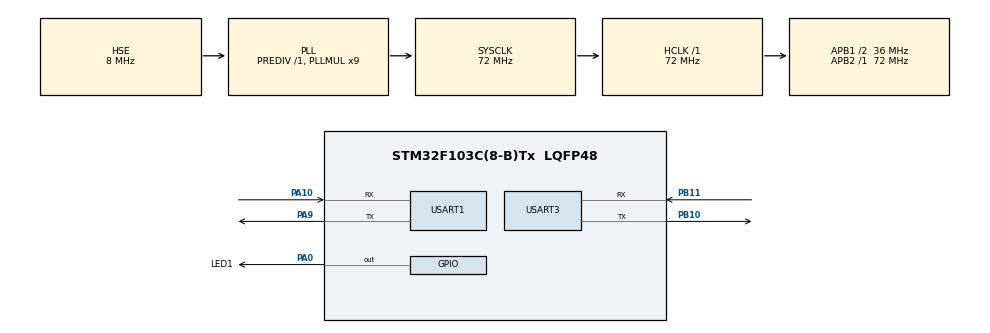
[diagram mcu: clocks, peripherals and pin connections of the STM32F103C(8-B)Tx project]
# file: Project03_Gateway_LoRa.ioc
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Dma.Request0=USART1_RX
Dma.Request1=USART3_RX
Dma.USART1_RX.0.Direction=DMA_PERIPH_TO_MEMORY
Dma.USART1_RX.0.Instance=DMA1_Channel5
Dma.USART1_RX.0.MemDataAlignment=DMA_MDATAALIGN_BYTE
Dma.USART1_RX.0.MemInc=DMA_MINC_ENABLE
Dma.USART1_RX.0.Mode=DMA_NORMAL
Dma.USART1_RX.0.PeriphDataAlignment=DMA_PDATAALIGN_BYTE
Dma.USART1_RX.0.PeriphInc=DMA_PINC_DISABLE
Dma.USART1_RX.0.Priority=DMA_PRIORITY_LOW
Dma.USART3_RX.1.Direction=DMA_PERIPH_TO_MEMORY
Dma.USART3_RX.1.Instance=DMA1_Channel3
Dma.USART3_RX.1.MemDataAlignment=DMA_MDATAALIGN_BYTE
Dma.USART3_RX.1.MemInc=DMA_MINC_ENABLE
Dma.USART3_RX.1.Mode=DMA_NORMAL
Dma.USART3_RX.1.PeriphDataAlignment=DMA_PDATAALIGN_BYTE
Dma.USART3_RX.1.PeriphInc=DMA_PINC_DISABLE
Dma.USART3_RX.1.Priority=DMA_PRIORITY_LOW
Mcu.Family=STM32F1
Mcu.Name=STM32F103C(8-B)Tx
Mcu.Package=LQFP48
NVIC.DMA1_Channel3_IRQn=true\:0\:0\:false\:false\:true\:false\:true\:true
NVIC.DMA1_Channel5_IRQn=true\:0\:0\:false\:false\:true\:false\:true\:true
NVIC.PriorityGroup=NVIC_PRIORITYGROUP_4
NVIC.USART1_IRQn=true\:0\:0\:false\:false\:true\:true\:true\:true
NVIC.USART3_IRQn=true\:0\:0\:false\:false\:true\:true\:true\:true
PA0-WKUP.GPIO_Label=LED1
PA0-WKUP.GPIO_Speed=GPIO_SPEED_FREQ_HIGH
PA0-WKUP.PinState=GPIO_PIN_SET
PA0-WKUP.Signal=GPIO_Output
PA10.Mode=Asynchronous
PA10.Signal=USART1_RX
PA13.Mode=Serial_Wire
PA13.Signal=SYS_JTMS-SWDIO
PA14.Mode=Serial_Wire
PA14.Signal=SYS_JTCK-SWCLK
PA9.Mode=Asynchronous
PA9.Signal=USART1_TX
PB10.Mode=Asynchronous
PB10.Signal=USART3_TX
PB11.Mode=Asynchronous
PB11.Signal=USART3_RX
PC14-OSC32_IN.Mode=LSE-External-Oscillator
PC14-OSC32_IN.Signal=RCC_OSC32_IN
PC15-OSC32_OUT.Mode=LSE-External-Oscillator
PC15-OSC32_OUT.Signal=RCC_OSC32_OUT
PD0-OSC_IN.Mode=HSE-External-Oscillator
PD0-OSC_IN.Signal=RCC_OSC_IN
PD1-OSC_OUT.Mode=HSE-External-Oscillator
PD1-OSC_OUT.Signal=RCC_OSC_OUT
ProjectManager.HeapSize=0x200
ProjectManager.StackSize=0x400
ProjectManager.TargetToolchain=MDK-ARM V5.32
RCC.AHBFreq_Value=72000000
RCC.APB1CLKDivider=RCC_HCLK_DIV2
RCC.APB1Freq_Value=36000000
RCC.APB1TimFreq_Value=72000000
RCC.APB2Freq_Value=72000000
RCC.APB2TimFreq_Value=72000000
RCC.HCLKFreq_Value=72000000
RCC.PLLMUL=RCC_PLL_MUL9
RCC.PLLSourceVirtual=RCC_PLLSOURCE_HSE
RCC.SYSCLKFreq_VALUE=72000000
RCC.SYSCLKSource=RCC_SYSCLKSOURCE_PLLCLK
RCC.USBFreq_Value=72000000
USART1.VirtualMode=VM_ASYNC
USART3.VirtualMode=VM_ASYNC
VP_CRC_VS_CRC.Mode=CRC_Activate
board=custom

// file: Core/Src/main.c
/* USER CODE BEGIN Header */
/**
  ******************************************************************************
  * @file           : main.c
  * @brief          : Main program body
  ******************************************************************************
  * @attention
  *
  * Copyright (c) 2026 STMicroelectronics.
  * All rights reserved.
  *
  * This software is licensed under terms that can be found in the LICENSE file
  * in the root directory of this software component.
  * If no LICENSE file comes with this software, it is provided AS-IS.
  *
  ******************************************************************************
  */
/* USER CODE END Header */
#include "main.h"
#include "crc.h"
#include "dma.h"
#include "usart.h"
#include "gpio.h"

/* USER CODE BEGIN Includes */
#include "lora_buf.h"               /* LoRa 串口帧缓冲层，提供 DMA+IDLE 帧接收队列 */
#include "app_update.h"             /* 网关端 LoRa 更新状态机，管理固件分发流程 */
#include "app_bootloader.h"         /* 网关 Bootloader 辅助定义（分区地址、跳转函数等） */
#include "uart_buf.h"               /* UART DMA+IDLE 帧缓冲，用于串口接收 PC 发送的 .bin 固件 */
#include "fw_cache_conf.h"          /* 固件缓存区配置：FW_CACHE_ADDR(0x08004000) 和大小定义 */
#include <stdio.h>                  /* printf 支持，通过 fputc 重定向到 USART1 输出调试日志 */
/* USER CODE END Includes */

/* USER CODE BEGIN PV */
static LORA_Buf_t lora_ctx;        /* LoRa 串口帧缓冲上下文，管理 USART3 DMA 接收和帧队列 */
static AppUpdate_t update_ctx;     /* 网关更新状态机上下文，驱动 LoRa 固件分发流程 */
/* USER CODE END PV */

void SystemClock_Config(void);

int main(void)
{

  /* MCU Configuration--------------------------------------------------------*/

  /* Reset of all peripherals, Initializes the Flash interface and the Systick. */
  HAL_Init();

  /* Configure the system clock */
  SystemClock_Config();

  /* Initialize all configured peripherals */
  MX_GPIO_Init();
  MX_DMA_Init();
  MX_USART1_UART_Init();
  MX_USART3_UART_Init();
  MX_CRC_Init();
  /* USER CODE BEGIN 2 */

  /*
   * LoRa 串口帧缓冲初始化
   * 绑定 USART3（LoRa 模块通信口）到帧缓冲上下文
   * 启动 DMA Normal 模式 + IDLE 线检测接收，用于接收 LoRa 协议帧
   */
  LORA_Buf_Init(&lora_ctx, &huart3);

  /*
   * 网关端 LoRa 更新状态机初始化
   *
   * 网关的职责是：
   * 1. 通过 USART1 串口从 PC 接收 .bin 固件文件，存储到内部 Flash 缓存区
   * 2. 通过 USART3 LoRa 模块将固件分帧发送给 App 节点
   *
   * FW_CACHE_ADDR = 0x08004000：固件在网关 Flash 中的缓存起始地址
   * 1344：固件大小（当前硬编码，待优化为动态读取）
   */
  AppUpdate_Init(&update_ctx, &lora_ctx,
                 (const uint8_t *)FW_CACHE_ADDR, 1344);

  /*
   * USART1 DMA 接收初始化
   * 用于从 PC 串口接收 .bin 固件数据流（UART 下载协议）
   * USART1 同时用于 printf 调试输出，DMA 仅用于接收方向
   */
  UART_DMA_Rx_Init();
  /* USER CODE END 2 */

  /* Infinite loop */
  while (1)
  {

    /* USER CODE BEGIN 3 */

    /*
     * 网关更新状态机轮询处理
     * 每轮循环检查两路输入：
     * 1. USART1 串口：检查是否有 PC 发来的固件数据（UART 下载协议）
     * 2. USART3 LoRa：检查是否有 App 节点发来的 UPDATE_REQ 等协议帧
     * 根据状态机当前状态驱动固件分发流程
     * 主循环不能有阻塞延时，以保证串口帧和 LoRa 帧都能及时处理
     */
    AppUpdate_Poll(&update_ctx);
  }
  /* USER CODE END 3 */
}

void SystemClock_Config(void)
{
  RCC_OscInitTypeDef RCC_OscInitStruct = {0};
  RCC_ClkInitTypeDef RCC_ClkInitStruct = {0};

  /** Initializes the RCC Oscillators according to the specified parameters
  * in the RCC_OscInitTypeDef structure.
  */
  RCC_OscInitStruct.OscillatorType = RCC_OSCILLATORTYPE_HSE;
  RCC_OscInitStruct.HSEState = RCC_HSE_ON;
  RCC_OscInitStruct.HSEPredivValue = RCC_HSE_PREDIV_DIV1;
  RCC_OscInitStruct.HSIState = RCC_HSI_ON;
  RCC_OscInitStruct.PLL.PLLState = RCC_PLL_ON;
  RCC_OscInitStruct.PLL.PLLSource = RCC_PLLSOURCE_HSE;
  RCC_OscInitStruct.PLL.PLLMUL = RCC_PLL_MUL9;
  if (HAL_RCC_OscConfig(&RCC_OscInitStruct) != HAL_OK)
  {
    Error_Handler();
  }

  /** Initializes the CPU, AHB and APB buses clocks
  */
  RCC_ClkInitStruct.ClockType = RCC_CLOCKTYPE_HCLK|RCC_CLOCKTYPE_SYSCLK
                              |RCC_CLOCKTYPE_PCLK1|RCC_CLOCKTYPE_PCLK2;
  RCC_ClkInitStruct.SYSCLKSource = RCC_SYSCLKSOURCE_PLLCLK;
  RCC_ClkInitStruct.AHBCLKDivider = RCC_SYSCLK_DIV1;
  RCC_ClkInitStruct.APB1CLKDivider = RCC_HCLK_DIV2;
  RCC_ClkInitStruct.APB2CLKDivider = RCC_HCLK_DIV1;

  if (HAL_RCC_ClockConfig(&RCC_ClkInitStruct, FLASH_LATENCY_2) != HAL_OK)
  {
    Error_Handler();
  }
}

void Error_Handler(void)
{
  __disable_irq();
  while (1)
  {
  }
}
